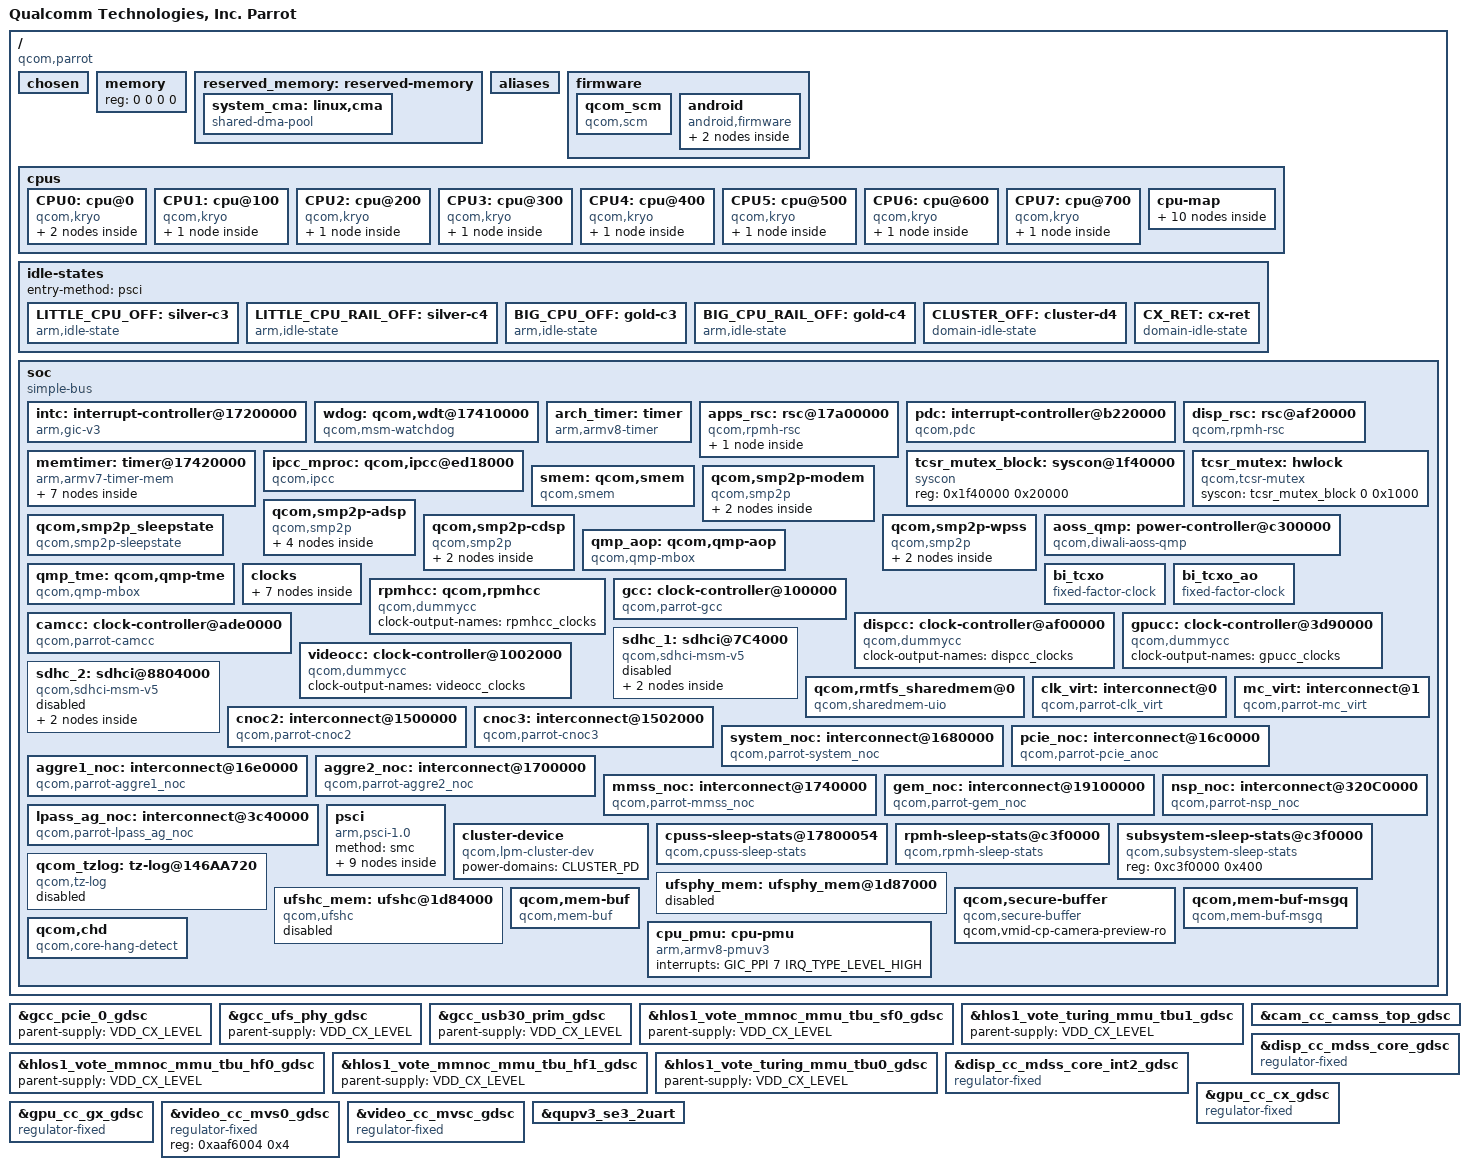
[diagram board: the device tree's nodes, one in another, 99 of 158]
#include <dt-bindings/interconnect/qcom,icc.h>
#include <dt-bindings/interconnect/qcom,parrot.h>
#include <dt-bindings/interrupt-controller/arm-gic.h>
#include <dt-bindings/soc/qcom,ipcc.h>
#include <dt-bindings/soc/qcom,rpmh-rsc.h>
#include <dt-bindings/clock/qcom,rpmh.h>
#include <dt-bindings/clock/qcom,camcc-parrot.h>
#include <dt-bindings/clock/qcom,dispcc-parrot.h>
#include <dt-bindings/clock/qcom,gcc-parrot.h>
#include <dt-bindings/clock/qcom,gpucc-parrot.h>
#include <dt-bindings/clock/qcom,videocc-parrot.h>

/ {
	model = "Qualcomm Technologies, Inc. Parrot";
	compatible = "qcom,parrot";
	qcom,msm-id = <537 0x10000>;
	interrupt-parent = <&intc>;

	#address-cells = <2>;
	#size-cells = <2>;

	chosen: chosen {
		stdout-path = "/soc/qcom,qup_uart@98C000:115200n8";
		bootargs = "console=ttyMSM0,115200n8 loglevel=8 log_buf_len=256K";
	};

	memory { device_type = "memory"; reg = <0 0 0 0>; };

	reserved_memory: reserved-memory { };

	aliases {
		mmc0 = &sdhc_1; /*SDC1 eMMC slot*/
		mmc1 = &sdhc_2; /* SDC2 SD card slot */
		ufshc1 = &ufshc_mem; /* Embedded UFS Slot */
		serial0 = &qupv3_se3_2uart;
	};

	firmware: firmware {};

	cpus {
		#address-cells = <2>;
		#size-cells = <0>;

		CPU0: cpu@0 {
			device_type = "cpu";
			compatible = "qcom,kryo";
			reg = <0x0 0x0>;
			enable-method = "psci";
			cpu-idle-states = <&LITTLE_CPU_OFF &LITTLE_CPU_RAIL_OFF>;
			power-domains = <&CPU_PD0>;
			power-domain-names = "psci";
			next-level-cache = <&L2_0>;
			L2_0: l2-cache {
				compatible = "arm,arch-cache";
				cache-level = <2>;
				next-level-cache = <&L3_0>;

				L3_0: l3-cache {
					compatible = "arm,arch-cache";
					cache-level = <3>;
				};
			};
		};

		CPU1: cpu@100 {
			device_type = "cpu";
			compatible = "qcom,kryo";
			reg = <0x0 0x100>;
			enable-method = "psci";
			cpu-idle-states = <&LITTLE_CPU_OFF &LITTLE_CPU_RAIL_OFF>;
			power-domains = <&CPU_PD1>;
			power-domain-names = "psci";
			next-level-cache = <&L2_1>;
			L2_1: l2-cache {
				compatible = "arm,arch-cache";
				cache-level = <2>;
				next-level-cache = <&L3_0>;
			};
		};

		CPU2: cpu@200 {
			device_type = "cpu";
			compatible = "qcom,kryo";
			reg = <0x0 0x200>;
			enable-method = "psci";
			cpu-idle-states = <&LITTLE_CPU_OFF &LITTLE_CPU_RAIL_OFF>;
			power-domains = <&CPU_PD2>;
			power-domain-names = "psci";
			next-level-cache = <&L2_2>;
			L2_2: l2-cache {
				compatible = "arm,arch-cache";
				cache-level = <2>;
				next-level-cache = <&L3_0>;
			};
		};

		CPU3: cpu@300 {
			device_type = "cpu";
			compatible = "qcom,kryo";
			reg = <0x0 0x300>;
			enable-method = "psci";
			cpu-idle-states = <&LITTLE_CPU_OFF &LITTLE_CPU_RAIL_OFF>;
			power-domains = <&CPU_PD3>;
			power-domain-names = "psci";
			next-level-cache = <&L2_3>;
			L2_3: l2-cache {
				compatible = "arm,arch-cache";
				cache-level = <2>;
				next-level-cache = <&L3_0>;
			};
		};

		CPU4: cpu@400 {
			device_type = "cpu";
			compatible = "qcom,kryo";
			reg = <0x0 0x400>;
			enable-method = "psci";
			cpu-idle-states = <&BIG_CPU_OFF &BIG_CPU_RAIL_OFF>;
			power-domains = <&CPU_PD4>;
			power-domain-names = "psci";
			L2_4: l2-cache {
				compatible = "arm,arch-cache";
				cache-level = <2>;
				next-level-cache = <&L3_0>;
			};
		};

		CPU5: cpu@500 {
			device_type = "cpu";
			compatible = "qcom,kryo";
			reg = <0x0 0x500>;
			enable-method = "psci";
			cpu-idle-states = <&BIG_CPU_OFF &BIG_CPU_RAIL_OFF>;
			power-domains = <&CPU_PD5>;
			power-domain-names = "psci";
			next-level-cache = <&L2_5>;
			L2_5: l2-cache {
				compatible = "arm,arch-cache";
				cache-level = <2>;
				next-level-cache = <&L3_0>;
			};
		};

		CPU6: cpu@600 {
			device_type = "cpu";
			compatible = "qcom,kryo";
			reg = <0x0 0x600>;
			enable-method = "psci";
			cpu-idle-states = <&BIG_CPU_OFF &BIG_CPU_RAIL_OFF>;
			power-domains = <&CPU_PD6>;
			power-domain-names = "psci";
			next-level-cache = <&L2_6>;
			L2_6: l2-cache {
				compatible = "arm,arch-cache";
				cache-level = <2>;
				next-level-cache = <&L3_0>;
			};
		};

		CPU7: cpu@700 {
			device_type = "cpu";
			compatible = "qcom,kryo";
			reg = <0x0 0x700>;
			enable-method = "psci";
			cpu-idle-states = <&BIG_CPU_OFF &BIG_CPU_RAIL_OFF>;
			power-domains = <&CPU_PD7>;
			power-domain-names = "psci";
			next-level-cache = <&L2_7>;
			L2_7: l2-cache {
				compatible = "arm,arch-cache";
				cache-level = <2>;
				next-level-cache = <&L3_0>;
			};
		};

		cpu-map {
			cluster0 {
				core0 {
					cpu = <&CPU0>;
				};

				core1 {
					cpu = <&CPU1>;
				};

				core2 {
					cpu = <&CPU2>;
				};

				core3 {
					cpu = <&CPU3>;
				};
			};

			cluster1 {
				core0 {
					cpu = <&CPU4>;
				};

				core1 {
					cpu = <&CPU5>;
				};

				core2 {
					cpu = <&CPU6>;
				};

				core3 {
					cpu = <&CPU7>;
				};
			};
		};
	};

	idle-states {
		entry-method = "psci";

		LITTLE_CPU_OFF: silver-c3 {  /* C3 */
			compatible = "arm,idle-state";
			idle-state-name = "pc";
			entry-latency-us = <350>;
			exit-latency-us = <900>;
			min-residency-us = <1774>;
			arm,psci-suspend-param = <0x40000003>;
			local-timer-stop;
		};

		LITTLE_CPU_RAIL_OFF: silver-c4 {  /* C4 */
			compatible = "arm,idle-state";
			idle-state-name = "rail-pc";
			entry-latency-us = <800>;
			exit-latency-us = <750>;
			min-residency-us = <4090>;
			arm,psci-suspend-param = <0x40000004>;
			local-timer-stop;
		};

		BIG_CPU_OFF: gold-c3 {  /* C3 */
			compatible = "arm,idle-state";
			idle-state-name = "pc";
			entry-latency-us = <400>;
			exit-latency-us = <1550>;
			min-residency-us = <2207>;
			arm,psci-suspend-param = <0x40000003>;
			local-timer-stop;
		};

		BIG_CPU_RAIL_OFF: gold-c4 {  /* C4 */
			compatible = "arm,idle-state";
			idle-state-name = "rail-pc";
			entry-latency-us = <600>;
			exit-latency-us = <1550>;
			min-residency-us = <4791>;
			arm,psci-suspend-param = <0x40000004>;
			local-timer-stop;
		};

		CLUSTER_OFF: cluster-d4 { /* D4 */
			compatible = "domain-idle-state";
			idle-state-name = "l3-off";
			entry-latency-us = <1050>;
			exit-latency-us = <2500>;
			min-residency-us = <5309>;
			arm,psci-suspend-param = <0x41000044>;
		};

		CX_RET: cx-ret { /* Cx Ret */
			compatible = "domain-idle-state";
			idle-state-name = "cx-ret";
			entry-latency-us = <1561>;
			exit-latency-us = <2801>;
			min-residency-us = <8550>;
			arm,psci-suspend-param = <0x41003344>;
		};
	};

	soc: soc { };

};

&firmware {
	qcom_scm {
		compatible = "qcom,scm";
	};

	android {
		compatible = "android,firmware";
		fstab {
			compatible = "android,fstab";
			vendor {
				compatible = "android,vendor";
				dev = "/dev/block/platform/soc/1d84000.ufshc/by-name/vendor";
				type = "ext4";
				mnt_flags = "ro,barrier=1,discard";
				fsmgr_flags = "wait,slotselect";
				status = "ok";
			};
		};
	};
};

#include "parrot-stub-regulator.dtsi"
#include "parrot-usb.dtsi"
#include "parrot-reserved-memory.dtsi"

&reserved_memory {
	#address-cells = <2>;
	#size-cells = <2>;
	ranges;

	/* global autoconfigured region for contiguous allocations */
	system_cma: linux,cma {
		compatible = "shared-dma-pool";
		alloc-ranges = <0x0 0x00000000 0x0 0xffffffff>;
		reusable;
		alignment = <0x0 0x400000>;
		size = <0x0 0x2000000>;
		linux,cma-default;
	};
};

&soc {
	#address-cells = <1>;
	#size-cells = <1>;
	ranges = <0 0 0 0xffffffff>;
	compatible = "simple-bus";

	intc: interrupt-controller@17200000 {
		compatible = "arm,gic-v3";
		#interrupt-cells = <3>;
		interrupt-controller;
		#redistributor-regions = <1>;
		redistributor-stride = <0x0 0x20000>;
		reg = <0x17200000 0x10000>,	/* GICD */
		      <0x17260000 0x100000>;	/* GICR * 8 */
		interrupts = <GIC_PPI 9 IRQ_TYPE_LEVEL_LOW>;
	};

	wdog: qcom,wdt@17410000 {
		compatible = "qcom,msm-watchdog";
		reg = <0x17410000 0x1000>;
		reg-names = "wdt-base";
		interrupts = <GIC_SPI 0 IRQ_TYPE_LEVEL_HIGH>,
			     <GIC_SPI 1 IRQ_TYPE_LEVEL_HIGH>;
		qcom,bark-time = <11000>;
		qcom,pet-time = <9360>;
		qcom,ipi-ping;
		qcom,wakeup-enable;
	};

	arch_timer: timer {
		compatible = "arm,armv8-timer";
		interrupts = <GIC_PPI 13 (GIC_CPU_MASK_SIMPLE(8) | IRQ_TYPE_LEVEL_LOW)>,
			     <GIC_PPI 14 (GIC_CPU_MASK_SIMPLE(8) | IRQ_TYPE_LEVEL_LOW)>,
			     <GIC_PPI 11 (GIC_CPU_MASK_SIMPLE(8) | IRQ_TYPE_LEVEL_LOW)>,
			     <GIC_PPI 12 (GIC_CPU_MASK_SIMPLE(8) | IRQ_TYPE_LEVEL_LOW)>;
		clock-frequency = <19200000>;
	};

	apps_rsc: rsc@17a00000 {
		label = "apps_rsc";
		compatible = "qcom,rpmh-rsc";
		reg = <0x17a00000 0x10000>,
		      <0x17a10000 0x10000>,
		      <0x17a20000 0x10000>;
		reg-names = "drv-0", "drv-1", "drv-2";
		interrupts = <GIC_SPI 3 IRQ_TYPE_LEVEL_HIGH>,
			     <GIC_SPI 4 IRQ_TYPE_LEVEL_HIGH>,
			     <GIC_SPI 5 IRQ_TYPE_LEVEL_HIGH>;
		qcom,tcs-offset = <0xd00>;
		qcom,drv-id = <2>;
		qcom,tcs-config = <ACTIVE_TCS    3>,
				  <SLEEP_TCS     2>,
				  <WAKE_TCS      2>,
				  <CONTROL_TCS   0>, /* PDC wakeup values will be written from TZ */
				  <FAST_PATH_TCS 1>;
		power-domains = <&CLUSTER_PD>;

		apps_bcm_voter: bcm_voter {
			compatible = "qcom,bcm-voter";
		};
	};

	pdc: interrupt-controller@b220000 {
		compatible = "qcom,pdc";
		reg = <0xb220000 0x30000>, <0x174000f0 0x64>;
		reg-names = "pdc-interrupt-base", "apss-shared-spi-cfg";
		qcom,pdc-ranges = <0 480 94>, <94 609 31>,
				  <125 63 1>, <126 716 12>;
		#interrupt-cells = <2>;
		interrupt-parent = <&intc>;
		interrupt-controller;
	};

	disp_rsc: rsc@af20000 {
		label = "disp_rsc";
		compatible = "qcom,rpmh-rsc";
		reg = <0xaf20000 0x10000>;
		reg-names = "drv-0";
		interrupts = <GIC_SPI 129 IRQ_TYPE_LEVEL_HIGH>;
		clocks = <&dispcc DISP_CC_MDSS_RSCC_AHB_CLK>;
		qcom,tcs-offset = <0x1c00>;
		qcom,drv-id = <0>;
		qcom,tcs-config = <ACTIVE_TCS    0>,
				  <SLEEP_TCS     1>,
				  <WAKE_TCS      1>,
				  <CONTROL_TCS   0>,
				  <FAST_PATH_TCS 0>;
	};

	memtimer: timer@17420000 {
		#address-cells = <1>;
		#size-cells = <1>;
		ranges;
		compatible = "arm,armv7-timer-mem";
		reg = <0x17420000 0x1000>;
		clock-frequency = <19200000>;

		frame@17421000 {
			frame-number = <0>;
			interrupts = <GIC_SPI 8 IRQ_TYPE_LEVEL_HIGH>,
				     <GIC_SPI 6 IRQ_TYPE_LEVEL_HIGH>;
			reg = <0x17421000 0x1000>,
			      <0x17422000 0x1000>;
		};

		frame@17423000 {
			frame-number = <1>;
			interrupts = <GIC_SPI 9 IRQ_TYPE_LEVEL_HIGH>;
			reg = <0x17423000 0x1000>;
			status = "disabled";
		};

		frame@17425000 {
			frame-number = <2>;
			interrupts = <GIC_SPI 10 IRQ_TYPE_LEVEL_HIGH>;
			reg = <0x17425000 0x1000>;
			status = "disabled";
		};

		frame@17427000 {
			frame-number = <3>;
			interrupts = <GIC_SPI 11 IRQ_TYPE_LEVEL_HIGH>;
			reg = <0x17427000 0x1000>;
			status = "disabled";
		};

		frame@17429000 {
			frame-number = <4>;
			interrupts = <GIC_SPI 12 IRQ_TYPE_LEVEL_HIGH>;
			reg = <0x17429000 0x1000>;
			status = "disabled";
		};

		frame@1742b000 {
			frame-number = <5>;
			interrupts = <GIC_SPI 13 IRQ_TYPE_LEVEL_HIGH>;
			reg = <0x1742b000 0x1000>;
			status = "disabled";
		};

		frame@1742d000 {
			frame-number = <6>;
			interrupts = <GIC_SPI 14 IRQ_TYPE_LEVEL_HIGH>;
			reg = <0x1742d000 0x1000>;
			status = "disabled";
		};
	};

	ipcc_mproc: qcom,ipcc@ed18000 {
		compatible = "qcom,ipcc";
		reg = <0xed18000 0x1000>;
		interrupts = <GIC_SPI 229 IRQ_TYPE_LEVEL_HIGH>;
		interrupt-controller;
		#interrupt-cells = <3>;
		#mbox-cells = <2>;
	};

	tcsr_mutex_block: syscon@1f40000 {
		compatible = "syscon";
		reg = <0x1f40000 0x20000>;
	};

	tcsr_mutex: hwlock {
		compatible = "qcom,tcsr-mutex";
		syscon = <&tcsr_mutex_block 0 0x1000>;
		#hwlock-cells = <1>;
	};

	smem: qcom,smem {
		compatible = "qcom,smem";
		memory-region = <&smem_mem>;
		hwlocks = <&tcsr_mutex 3>;
	};

	qcom,smp2p-modem {
		compatible = "qcom,smp2p";
		qcom,smem = <435>, <428>;
		interrupt-parent = <&ipcc_mproc>;
		interrupts = <IPCC_CLIENT_MPSS IPCC_MPROC_SIGNAL_SMP2P
				IRQ_TYPE_EDGE_RISING>;
		mboxes = <&ipcc_mproc IPCC_CLIENT_MPSS IPCC_MPROC_SIGNAL_SMP2P>;
		qcom,local-pid = <0>;
		qcom,remote-pid = <1>;

		modem_smp2p_out: master-kernel {
			qcom,entry-name = "master-kernel";
			#qcom,smem-state-cells = <1>;
		};

		modem_smp2p_in: slave-kernel {
			qcom,entry-name = "slave-kernel";
			interrupt-controller;
			#interrupt-cells = <2>;
		};
	};

	qcom,smp2p-adsp {
		compatible = "qcom,smp2p";
		qcom,smem = <443>, <429>;
		interrupt-parent = <&ipcc_mproc>;
		interrupts = <IPCC_CLIENT_LPASS IPCC_MPROC_SIGNAL_SMP2P
			      IRQ_TYPE_EDGE_RISING>;
		mboxes = <&ipcc_mproc IPCC_CLIENT_LPASS
			  IPCC_MPROC_SIGNAL_SMP2P>;
		qcom,local-pid = <0>;
		qcom,remote-pid = <2>;

		adsp_smp2p_out: master-kernel {
			qcom,entry-name = "master-kernel";
			#qcom,smem-state-cells = <1>;
		};

		adsp_smp2p_in: slave-kernel {
			qcom,entry-name = "slave-kernel";
			interrupt-controller;
			#interrupt-cells = <2>;
		};

		sleepstate_smp2p_out: sleepstate-out {
			qcom,entry-name = "sleepstate";
			#qcom,smem-state-cells = <1>;
		};

		sleepstate_smp2p_in: qcom,sleepstate-in {
			qcom,entry-name = "sleepstate_see";
			interrupt-controller;
			#interrupt-cells = <2>;
		};
	};

	qcom,smp2p_sleepstate {
		compatible = "qcom,smp2p-sleepstate";
		qcom,smem-states = <&sleepstate_smp2p_out 0>;
		interrupt-parent = <&sleepstate_smp2p_in>;
		interrupts = <0 0>;
		interrupt-names = "smp2p-sleepstate-in";
	};

	qcom,smp2p-cdsp {
		compatible = "qcom,smp2p";
		qcom,smem = <94>, <432>;
		interrupt-parent = <&ipcc_mproc>;
		interrupts = <IPCC_CLIENT_CDSP IPCC_MPROC_SIGNAL_SMP2P
				IRQ_TYPE_EDGE_RISING>;
		mboxes = <&ipcc_mproc IPCC_CLIENT_CDSP IPCC_MPROC_SIGNAL_SMP2P>;
		qcom,local-pid = <0>;
		qcom,remote-pid = <5>;

		cdsp_smp2p_out: master-kernel {
			qcom,entry-name = "master-kernel";
			#qcom,smem-state-cells = <1>;
		};

		cdsp_smp2p_in: slave-kernel {
			qcom,entry-name = "slave-kernel";
			interrupt-controller;
			#interrupt-cells = <2>;
		};
	};

	qcom,smp2p-wpss {
		compatible = "qcom,smp2p";
		qcom,smem = <617>, <616>;
		interrupt-parent = <&ipcc_mproc>;
		interrupts = <IPCC_CLIENT_WPSS IPCC_MPROC_SIGNAL_SMP2P
			IRQ_TYPE_EDGE_RISING>;
		mboxes = <&ipcc_mproc IPCC_CLIENT_WPSS IPCC_MPROC_SIGNAL_SMP2P>;
		qcom,local-pid = <0>;
		qcom,remote-pid = <13>;

		wpss_smp2p_out: master-kernel {
			qcom,entry-name = "master-kernel";
			#qcom,smem-state-cells = <1>;
		};

		wpss_smp2p_in: slave-kernel {
			qcom,entry-name = "slave-kernel";
			interrupt-controller;
			#interrupt-cells = <2>;
		};
	};

	aoss_qmp: power-controller@c300000 {
		compatible = "qcom,diwali-aoss-qmp";
		reg = <0xc300000 0x400>;
		interrupt-parent = <&ipcc_mproc>;
		interrupts = <IPCC_CLIENT_AOP
				IPCC_MPROC_SIGNAL_GLINK_QMP
				IRQ_TYPE_EDGE_RISING>;
		mboxes = <&ipcc_mproc IPCC_CLIENT_AOP
				IPCC_MPROC_SIGNAL_GLINK_QMP>;

		#power-domain-cells = <1>;
		#clock-cells = <0>;
	};

	qmp_aop: qcom,qmp-aop {
		compatible = "qcom,qmp-mbox";
		qcom,qmp = <&aoss_qmp>;
		label = "aop";
		#mbox-cells = <1>;
	};

	qmp_tme: qcom,qmp-tme {
		compatible = "qcom,qmp-mbox";
		qcom,remote-pid = <14>;
		mboxes = <&ipcc_mproc IPCC_CLIENT_TME
				IPCC_MPROC_SIGNAL_GLINK_QMP>;
		mbox-names = "tme_qmp";
		interrupt-parent = <&ipcc_mproc>;
		interrupts = <IPCC_CLIENT_TME
				IPCC_MPROC_SIGNAL_GLINK_QMP
				IRQ_TYPE_EDGE_RISING>;

		label = "tme";
		qcom,early-boot;
		priority = <0>;
		mbox-desc-offset = <0x0>;
		#mbox-cells = <1>;
	};

	clocks {
		xo_board: xo-board {
			compatible = "fixed-clock";
			clock-frequency = <38400000>;
			clock-output-names = "xo_board";
			#clock-cells = <0>;
		};

		sleep_clk: sleep-clk {
			compatible = "fixed-clock";
			clock-frequency = <32000>;
			clock-output-names = "sleep_clk";
			#clock-cells = <0>;
		};

		pcie_0_pipe_clk: pcie_0_pipe_clk {
			compatible = "fixed-clock";
			clock-frequency = <1000>;
			clock-output-names = "pcie_0_pipe_clk";
			#clock-cells = <0>;
		};

		ufs_phy_rx_symbol_0_clk: ufs_phy_rx_symbol_0_clk {
			compatible = "fixed-clock";
			clock-frequency = <1000>;
			clock-output-names = "ufs_phy_rx_symbol_0_clk";
			#clock-cells = <0>;
		};

		ufs_phy_rx_symbol_1_clk: ufs_phy_rx_symbol_1_clk {
			compatible = "fixed-clock";
			clock-frequency = <1000>;
			clock-output-names = "ufs_phy_rx_symbol_1_clk";
			#clock-cells = <0>;
		};

		ufs_phy_tx_symbol_0_clk: ufs_phy_tx_symbol_0_clk {
			compatible = "fixed-clock";
			clock-frequency = <1000>;
			clock-output-names = "ufs_phy_tx_symbol_0_clk";
			#clock-cells = <0>;
		};

		usb3_phy_wrapper_gcc_usb30_pipe_clk: usb3_phy_wrapper_gcc_usb30_pipe_clk {
			compatible = "fixed-clock";
			clock-frequency = <1000>;
			clock-output-names = "usb3_phy_wrapper_gcc_usb30_pipe_clk";
			#clock-cells = <0>;
		};
	};

	bi_tcxo: bi_tcxo {
		compatible = "fixed-factor-clock";
		clock-mult = <1>;
		clock-div = <2>;
		clocks = <&xo_board>;
		#clock-cells = <0>;
	};

	bi_tcxo_ao: bi_tcxo_ao {
		compatible = "fixed-factor-clock";
		clock-mult = <1>;
		clock-div = <2>;
		clocks = <&xo_board>;
		#clock-cells = <0>;
	};

	rpmhcc: qcom,rpmhcc {
		compatible = "qcom,dummycc";
		clock-output-names = "rpmhcc_clocks";
		#clock-cells = <1>;
		#reset-cells = <1>;
	};

	gcc: clock-controller@100000 {
		compatible = "qcom,parrot-gcc", "syscon";
		reg = <0x100000 0x1f4200>;
		reg-name = "cc_base";
		vdd_cx-supply = <&VDD_CX_LEVEL>;
		vdd_mxa-supply = <&VDD_MXA_LEVEL>;
		clocks = <&rpmhcc RPMH_CXO_CLK>, <&sleep_clk>,
			<&pcie_0_pipe_clk>, <&ufs_phy_rx_symbol_0_clk>,
			<&ufs_phy_rx_symbol_1_clk>, <&ufs_phy_tx_symbol_0_clk>,
			<&usb3_phy_wrapper_gcc_usb30_pipe_clk>;
		clock-names = "bi_tcxo", "sleep_clk",
			"pcie_0_pipe_clk", "ufs_phy_rx_symbol_0_clk",
			"ufs_phy_rx_symbol_1_clk", "ufs_phy_tx_symbol_0_clk",
			"usb3_phy_wrapper_gcc_usb30_pipe_clk";
		#clock-cells = <1>;
		#reset-cells = <1>;
	};

	camcc: clock-controller@ade0000 {
		compatible = "qcom,parrot-camcc", "syscon";
		reg = <0xade0000 0x20000>;
		reg-name = "cc_base";
		vdd_cx-supply = <&VDD_CX_LEVEL>;
		vdd_mxa-supply = <&VDD_MXA_LEVEL>;
		clocks = <&rpmhcc RPMH_CXO_CLK>,
			<&gcc GCC_CAMERA_AHB_CLK>;
		clock-names = "bi_tcxo", "iface";
		#clock-cells = <1>;
		#reset-cells = <1>;
	};

	dispcc: clock-controller@af00000 {
		compatible = "qcom,dummycc";
		clock-output-names = "dispcc_clocks";
		#clock-cells = <1>;
		#reset-cells = <1>;
	};

	gpucc: clock-controller@3d90000 {
		compatible = "qcom,dummycc";
		clock-output-names = "gpucc_clocks";
		#clock-cells = <1>;
		#reset-cells = <1>;
	};

	videocc: clock-controller@1002000 {
		compatible = "qcom,dummycc";
		clock-output-names = "videocc_clocks";
		#clock-cells = <1>;
		#reset-cells = <1>;
	};

	sdhc_1: sdhci@7C4000 {
		status = "disabled";

		compatible = "qcom,sdhci-msm-v5";
		reg = <0x007C4000 0x1000>, <0x007C5000 0x1000>;
		reg-names = "hc", "cqhci";

		interrupts = <GIC_SPI 135 IRQ_TYPE_LEVEL_HIGH>,
				<GIC_SPI 137 IRQ_TYPE_LEVEL_HIGH>;
		interrupt-names = "hc_irq", "pwr_irq";

		bus-width = <8>;
		non-removable;
		supports-cqe;

		no-sd;
		no-sdio;

		mmc-ddr-1_8v;
		mmc-hs200-1_8v;
		mmc-hs400-1_8v;
		mmc-hs400-enhanced-strobe;

		clocks = <&gcc GCC_SDCC1_AHB_CLK>,
			<&gcc GCC_SDCC1_APPS_CLK>,
			<&gcc GCC_SDCC1_ICE_CORE_CLK>;
		clock-names = "iface", "core", "ice_core";

		qcom,ice-clk-rates = <300000000 100000000>;

		qos0 {
			mask = <0xf0>;
			vote = <44>;
		};

		qos1 {
			mask = <0x0f>;
			vote = <44>;
		};
	};

	sdhc_2: sdhci@8804000 {
		status = "disabled";

		compatible = "qcom,sdhci-msm-v5";
		reg = <0x08804000 0x1000>;
		reg-names = "hc";

		interrupts = <GIC_SPI 207 IRQ_TYPE_LEVEL_HIGH>,
				<GIC_SPI 223 IRQ_TYPE_LEVEL_HIGH>;
		interrupt-names = "hc_irq", "pwr_irq";

		bus-width = <4>;
		no-sdio;
		no-mmc;
		qcom,restore-after-cx-collapse;

		clocks = <&gcc GCC_SDCC2_AHB_CLK>,
			<&gcc GCC_SDCC2_APPS_CLK>;
		clock-names = "iface", "core";

		qos0 {
			mask = <0xf0>;
			vote = <44>;
		};

		qos1 {
			mask = <0x0f>;
			vote = <44>;
		};
	};

	qcom,rmtfs_sharedmem@0 {
		compatible = "qcom,sharedmem-uio";
		reg = <0x0 0x280000>;
		reg-names = "rmtfs";
		qcom,client-id = <0x00000001>;
	};

	clk_virt: interconnect@0 {
		compatible = "qcom,parrot-clk_virt";
		qcom,bcm-voter-names = "hlos";
		qcom,bcm-voters = <&apps_bcm_voter>;
		#interconnect-cells = <1>;
	};

	mc_virt: interconnect@1 {
		compatible = "qcom,parrot-mc_virt";
		qcom,bcm-voter-names = "hlos";
		qcom,bcm-voters = <&apps_bcm_voter>;
		#interconnect-cells = <1>;
	};

	cnoc2: interconnect@1500000 {
		reg = <0x1500000 0x1000>;
		compatible = "qcom,parrot-cnoc2";
		qcom,bcm-voter-names = "hlos";
		qcom,bcm-voters = <&apps_bcm_voter>;
		#interconnect-cells = <1>;
	};

	cnoc3: interconnect@1502000 {
		reg = <0x1502000 0x1000>;
		compatible = "qcom,parrot-cnoc3";
		qcom,bcm-voter-names = "hlos";
		qcom,bcm-voters = <&apps_bcm_voter>;
		#interconnect-cells = <1>;
	};

	system_noc: interconnect@1680000 {
		reg = <0x1680000 0x1E200>;
		compatible = "qcom,parrot-system_noc";
		qcom,bcm-voter-names = "hlos";
		qcom,bcm-voters = <&apps_bcm_voter>;
		#interconnect-cells = <1>;
	};

	pcie_noc: interconnect@16c0000 {
		reg = <0x16C0000 0xE280>;
		compatible = "qcom,parrot-pcie_anoc";
		qcom,bcm-voter-names = "hlos";
		qcom,bcm-voters = <&apps_bcm_voter>;
		#interconnect-cells = <1>;
	};

	aggre1_noc: interconnect@16e0000 {
		reg = <0x16e0000 0x1C080>;
		compatible = "qcom,parrot-aggre1_noc";
		qcom,bcm-voter-names = "hlos";
		qcom,bcm-voters = <&apps_bcm_voter>;
		#interconnect-cells = <1>;
	};

	aggre2_noc: interconnect@1700000 {
		reg = <0x1700000 0x31080>;
		compatible = "qcom,parrot-aggre2_noc";
		qcom,bcm-voter-names = "hlos";
		qcom,bcm-voters = <&apps_bcm_voter>;
		#interconnect-cells = <1>;
	};

	mmss_noc: interconnect@1740000 {
		reg = <0x1740000 0x1f080>;
		compatible = "qcom,parrot-mmss_noc";
		qcom,bcm-voter-names = "hlos";
		qcom,bcm-voters = <&apps_bcm_voter>;
		#interconnect-cells = <1>;
	};

	gem_noc: interconnect@19100000 {
		reg = <0x19100000 0xBB800>;
		compatible = "qcom,parrot-gem_noc";
		qcom,bcm-voter-names = "hlos";
		qcom,bcm-voters = <&apps_bcm_voter>;
		#interconnect-cells = <1>;
	};

	nsp_noc: interconnect@320C0000 {
		reg = <0x320C0000 0x10000>;
		compatible = "qcom,parrot-nsp_noc";
		qcom,bcm-voter-names = "hlos";
		qcom,bcm-voters = <&apps_bcm_voter>;
		#interconnect-cells = <1>;
	};

	lpass_ag_noc: interconnect@3c40000 {
		reg = <0x3c40000 0x17200>;
		compatible = "qcom,parrot-lpass_ag_noc";
		qcom,bcm-voter-names = "hlos";
		qcom,bcm-voters = <&apps_bcm_voter>;
		#interconnect-cells = <1>;
	};

	psci {
		compatible = "arm,psci-1.0";
		method = "smc";

		CPU_PD0: cpu-pd0 {
			#power-domain-cells = <0>;
			power-domains = <&CLUSTER_PD>;
		};

		CPU_PD1: cpu-pd1 {
			#power-domain-cells = <0>;
			power-domains = <&CLUSTER_PD>;
		};

		CPU_PD2: cpu-pd2 {
			#power-domain-cells = <0>;
			power-domains = <&CLUSTER_PD>;
		};

		CPU_PD3: cpu-pd3 {
			#power-domain-cells = <0>;
			power-domains = <&CLUSTER_PD>;
		};

		CPU_PD4: cpu-pd4 {
			#power-domain-cells = <0>;
			power-domains = <&CLUSTER_PD>;
		};

		CPU_PD5: cpu-pd5 {
			#power-domain-cells = <0>;
			power-domains = <&CLUSTER_PD>;
		};

		CPU_PD6: cpu-pd6 {
			#power-domain-cells = <0>;
			power-domains = <&CLUSTER_PD>;
		};

		CPU_PD7: cpu-pd7 {
			#power-domain-cells = <0>;
			power-domains = <&CLUSTER_PD>;
		};

		CLUSTER_PD: cluster-pd {
			#power-domain-cells = <0>;
			domain-idle-states = <&CLUSTER_OFF &CX_RET>;
		};
	};

	cluster-device {
		compatible = "qcom,lpm-cluster-dev";
		power-domains = <&CLUSTER_PD>;
	};

	cpuss-sleep-stats@17800054 {
		compatible = "qcom,cpuss-sleep-stats";
		reg = <0x17800054 0x4>, <0x17810054 0x4>, <0x17820054 0x4>,
		    <0x17830054 0x4>, <0x17840054 0x4>, <0x17850054 0x4>,
		    <0x17860054 0x4>, <0x17870054 0x4>, <0x178A0098 0x4>,
		    <0x178C0000 0x10000>;
		reg-names = "seq_lpm_cntr_cfg_cpu0", "seq_lpm_cntr_cfg_cpu1",
			  "seq_lpm_cntr_cfg_cpu2", "seq_lpm_cntr_cfg_cpu3",
			  "seq_lpm_cntr_cfg_cpu4", "seq_lpm_cntr_cfg_cpu5",
			  "seq_lpm_cntr_cfg_cpu6", "seq_lpm_cntr_cfg_cpu7",
			  "l3_seq_lpm_cntr_cfg", "apss_seq_mem_base";
		num-cpus = <8>;
	};

	rpmh-sleep-stats@c3f0000 {
		compatible = "qcom,rpmh-sleep-stats";
		reg = <0xc3f0000 0x400>;
		ss-name = "modem", "adsp", "adsp_island",
			  "cdsp", "apss", "wpss";
	};

	subsystem-sleep-stats@c3f0000 {
		compatible = "qcom,subsystem-sleep-stats";
		reg = <0xc3f0000 0x400>;
	};

	qcom_tzlog: tz-log@146AA720 {
		compatible = "qcom,tz-log";
		reg = <0x146AA720 0x3000>;
		qcom,hyplog-enabled;
		hyplog-address-offset = <0x410>;
		hyplog-size-offset = <0x414>;
		status = "disabled";
	};

	ufsphy_mem: ufsphy_mem@1d87000 {
		reg = <0x1d87000 0xe10>;
		reg-names = "phy_mem";
		#phy-cells = <0>;

		lanes-per-direction = <2>;
		clock-names = "ref_clk_src",
			"ref_aux_clk", "qref_clk";
		clocks = <&rpmhcc RPMH_CXO_CLK>,
			<&gcc GCC_UFS_PHY_PHY_AUX_CLK>,
			<&gcc GCC_UFS_0_CLKREF_EN>;
		resets = <&ufshc_mem 0>;
		status = "disabled";
	};

	ufshc_mem: ufshc@1d84000 {
		compatible = "qcom,ufshc";
		reg = <0x1d84000 0x3000>;
		reg-names = "ufs_mem";
		interrupts = <GIC_SPI 265 IRQ_TYPE_LEVEL_HIGH>;
		phys = <&ufsphy_mem>;
		phy-names = "ufsphy";
		#reset-cells = <1>;

		lanes-per-direction = <2>;
		dev-ref-clk-freq = <0>; /* 19.2 MHz */
		clock-names =
			"core_clk",
			"bus_aggr_clk",
			"iface_clk",
			"core_clk_unipro",
			"core_clk_ice",
			"ref_clk",
			"tx_lane0_sync_clk",
			"rx_lane0_sync_clk",
			"rx_lane1_sync_clk";
		clocks =
			<&gcc GCC_UFS_PHY_AXI_CLK>,
			<&gcc GCC_AGGRE_UFS_PHY_AXI_CLK>,
			<&gcc GCC_UFS_PHY_AHB_CLK>,
			<&gcc GCC_UFS_PHY_UNIPRO_CORE_CLK>,
			<&gcc GCC_UFS_PHY_ICE_CORE_CLK>,
			<&rpmhcc RPMH_CXO_CLK>,
			<&gcc GCC_UFS_PHY_TX_SYMBOL_0_CLK>,
			<&gcc GCC_UFS_PHY_RX_SYMBOL_0_CLK>,
			<&gcc GCC_UFS_PHY_RX_SYMBOL_1_CLK>;
		freq-table-hz =
			<75000000 300000000>,
			<0 0>,
			<0 0>,
			<75000000 300000000>,
			<75000000 300000000>,
			<0 0>,
			<0 0>,
			<0 0>,
			<0 0>;

		iommus = <&apps_smmu 0x20 0x0>;
		dma-coherent;

		status = "disabled";
	};

	qcom,secure-buffer {
		compatible = "qcom,secure-buffer";
		qcom,vmid-cp-camera-preview-ro;
	};

	qcom,mem-buf {
		compatible = "qcom,mem-buf";
		qcom,mem-buf-capabilities = "supplier";
		qcom,vmid = <3>;
	};

	qcom,mem-buf-msgq {
		compatible = "qcom,mem-buf-msgq";
	};

	 qcom,chd {
		compatible = "qcom,core-hang-detect";
		label = "core";
		qcom,threshold-arr = <0x17800058 0x17810058 0x17820058 0x17830058
				0x17840058 0x17850058 0x17860058 0x17870058>;
		qcom,config-arr = <0x17800060 0x17810060 0x17820060 0x17830060
				0x17840060 0x17850060 0x17860060 0x17870060>;
	};

	cpu_pmu: cpu-pmu {
		compatible = "arm,armv8-pmuv3";
		interrupts = <GIC_PPI 7 IRQ_TYPE_LEVEL_HIGH>;
	};
};

#include "diwali-gdsc.dtsi"
#include "ipcc-test-parrot.dtsi"

&gcc_pcie_0_gdsc {
	/delete-property/ qcom,support-hw-trigger;
	parent-supply = <&VDD_CX_LEVEL>;
	status = "ok";
};

&gcc_ufs_phy_gdsc {
	parent-supply = <&VDD_CX_LEVEL>;
	status = "ok";
};

&gcc_usb30_prim_gdsc {
	parent-supply = <&VDD_CX_LEVEL>;
	status = "ok";
};

&hlos1_vote_mmnoc_mmu_tbu_sf0_gdsc {
	parent-supply = <&VDD_CX_LEVEL>;
	status = "ok";
};

&hlos1_vote_turing_mmu_tbu1_gdsc {
	parent-supply = <&VDD_CX_LEVEL>;
	status = "ok";
};

&hlos1_vote_mmnoc_mmu_tbu_hf0_gdsc {
	parent-supply = <&VDD_CX_LEVEL>;
	status = "ok";
};

&hlos1_vote_mmnoc_mmu_tbu_hf1_gdsc {
	parent-supply = <&VDD_CX_LEVEL>;
	status = "ok";
};

&hlos1_vote_turing_mmu_tbu0_gdsc {
	parent-supply = <&VDD_CX_LEVEL>;
	status = "ok";
};

&cam_cc_camss_top_gdsc {
	parent-supply = <&VDD_CX_LEVEL>;
	clocks = <&gcc GCC_CAMERA_AHB_CLK>;
	clock-names = "ahb_clk";
	status = "ok";
};

&disp_cc_mdss_core_gdsc {
	compatible = "regulator-fixed";
	/delete-property/ qcom,support-hw-trigger;
	status = "ok";
};

&disp_cc_mdss_core_int2_gdsc {
	compatible = "regulator-fixed";
	/delete-property/ qcom,support-hw-trigger;
	status = "ok";
};

&gpu_cc_cx_gdsc {
	compatible = "regulator-fixed";
	status = "ok";
};

&gpu_cc_gx_gdsc {
	compatible = "regulator-fixed";
	status = "ok";
};

&video_cc_mvs0_gdsc {
	compatible = "regulator-fixed";
	reg = <0xaaf6004 0x4>;
	status = "ok";
	/delete-property/ qcom,support-hw-trigger;
};

&video_cc_mvsc_gdsc {
	compatible = "regulator-fixed";
	status = "ok";
};

#include "parrot-qupv3.dtsi"
#include "parrot-pinctrl.dtsi"
#include "parrot-dma-heaps.dtsi"
#include "msm-arm-smmu-parrot.dtsi"

&qupv3_se3_2uart {
	status = "ok";
};
